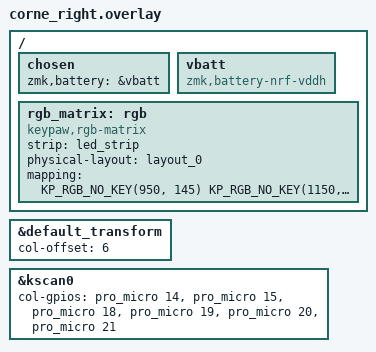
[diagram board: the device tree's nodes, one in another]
/*
 * Copyright (c) 2020 Pete Johanson
 *
 * SPDX-License-Identifier: MIT
 */

#include "corne.dtsi"

&default_transform {
	col-offset = <6>;
};

&kscan0 {
    col-gpios
        = <&pro_micro 14  GPIO_ACTIVE_HIGH>
        , <&pro_micro 15  GPIO_ACTIVE_HIGH>
        , <&pro_micro 18  GPIO_ACTIVE_HIGH>
        , <&pro_micro 19  GPIO_ACTIVE_HIGH>
        , <&pro_micro 20  GPIO_ACTIVE_HIGH>
        , <&pro_micro 21  GPIO_ACTIVE_HIGH>
        ;
};
/ {
    chosen {
      zmk,battery = &vbatt;
    };

    vbatt: vbatt {
        compatible = "zmk,battery-nrf-vddh";
    };
};

#include <dt-bindings/keypaw/rgb_matrix.h>

/ {
    /* Mapa da cadeia de LEDs desta metade. É uma PROPOSTA baseada no QMK
       (crkbd/rev1), ainda não confirmada no teclado. Veja o README. */
    rgb_matrix: rgb {
        compatible = "keypaw,rgb-matrix";
        #binding-cells = <2>;
        strip = <&led_strip>;
        physical-layout = <&layout_0>;
        mapping = <
        /* Seis LEDs de underglow (os grandes). As coordenadas são aproximadas: cada um
           fica logo abaixo da tecla indicada. Ordem: abaixo de LED39, LED37, LED35,
           LED41, LED49 e LED51 (números gravados na placa). */
        KP_RGB_NO_KEY(950, 145)
        KP_RGB_NO_KEY(1150, 100)
        KP_RGB_NO_KEY(1350, 205)
        KP_RGB_NO_KEY(1350, 305)
        KP_RGB_NO_KEY(1150, 300)
        KP_RGB_NO_KEY(950, 345)

        /* 21 LEDs por tecla, na ordem da cadeia (posições de tecla do keymap) */
        39 30 18 6 7 19 31 40 41 32 20 8 9 21 33 34 22 10 11 23 35
        >;
    };
};

#include "corne-rgb-effects.dtsi"
